# nrf7140_wificore register map
Vendor: Nordic Semiconductor; Series: nRF71; File version: 1
Registers are 32-bit, read-write, reset 0x0 unless marked. A register's access mark holds for its fields unless they carry their own. Offsets are from the block's base; [hi:lo] are bit positions; lines under a group give offsets from that group; {n}, {i} and the like mark numbered series.

## GLOBAL_COEXC — Coexistence controller
Base 0x5F92E000
{0x400+0x20*i} CCMALLOW[{i}] (i=0..5) group — Unspecified
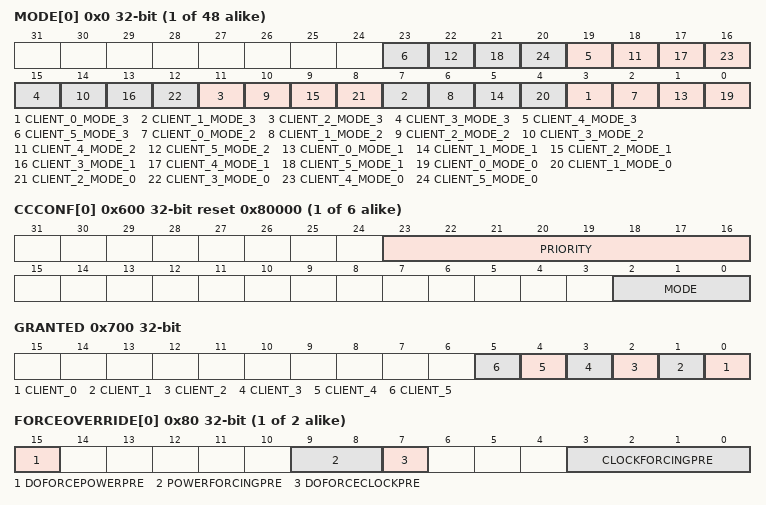
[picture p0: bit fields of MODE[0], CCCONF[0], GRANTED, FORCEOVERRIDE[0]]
  {0x0+4j} MODE[{j}] (j=0..7) — Description collection: Coexistence client mode allow configuration for mode [o] in client [n]
    [all] fields
      0=NotAllowed (Coexistence not allowed); 1=Allow (Coexistence allowed)
    [4n+3] CLIENT_{n}_MODE_3 (n=0..5) — Coexistence allowed configuration for mode [3] in client [{n}]
    [4n+2] CLIENT_{n}_MODE_2 (n=0..5) — Coexistence allowed configuration for mode [2] in client [{n}]
    [4n+1] CLIENT_{n}_MODE_1 (n=0..5) — Coexistence allowed configuration for mode [1] in client [{n}]
    [4n] CLIENT_{n}_MODE_0 (n=0..5) — Coexistence allowed configuration for mode [0] in client [{n}]
{0x600+4i} CCCONF[{i}] (i=0..5) reset 0x80000 — Description collection: Configuration of coexistence client [n]
  [23:16] PRIORITY — Priority of the coexistence client [n]
  [2:0] MODE — Coexistence mode of the client [m]
{0x640+4i} TURNAROUND[{i}] (i=0..5) reset 0x280 — Description collection: Turnaround time for the coexistence client [n]
  [11:0] CLOCKCYCLES — Number of clock cycles
0x700 GRANTED ro — Granted status of the shared resource
  [n] CLIENT_{n} (n=0..5) — Granted status coexistence client [{n}]
    0=NotGranted (Shared resource is not granted for coexistence client [{n}]); 1=Granted (Shared resource is granted for coexistence client [{n}])
0xC00 PCGCSLAVE group — Unspecified
  {0x0+4j} PENALTY[{j}] (j=0..1) reset 0xFFFFFFFC — Description collection: Penalty level for power/clock pair n. When FULL_PCP_ZERO feature is not supported, PENALTY[0] address overlaps the PENALTY0 address and register description for PENALTY[0] is not valid.
    [1:0] PENALTY — Penalty level
  0x00 PENALTY0 (alternate view of PENALTY[*]) — Penalty level for power/clock pair 0. The register description is valid only when FULL_PCP_ZERO feature is not supported
    [1:0] PENALTY ro — Penalty level
  {0x80+4j} FORCEOVERRIDE[{j}] (j=0..1) — Description collection: Force override of power/clock pair n.
    [15] DOFORCEPOWERPRE, [9:8] POWERFORCINGPRE, [7] DOFORCECLOCKPRE, [3:0] CLOCKFORCINGPRE

## GLOBAL_GPIOINTERNAL — GPIO Internal
Base 0x5F939E00
0x40 LATCHCLRWAITCNT reset 0x2 — Select the number of wait cycles inserted on the bus when a LATCH register is cleared.
  [1:0] LATCHCLRWAITCNT
0x44 FORCELDETECTLOWCNT reset 0x8 — Select the number of cycles that LDETECT is forced low after clearing a LATCH register.
  [3:0] FORCELDETECTLOWCNT
0x48 RESET — Reset all GPIO registers.
  [0] RESET
    1=RESET (Trigger reset); 0=NA (No effect)
0x4C SENSECONFIGCHANGECNT reset 0x3 — Selects the number of cycles before the SENSE configuration takes effect when it is changed. Setting this register lower than the reset value can lead to unwanted LATCH set when SENSE and INPUT fields (PIN[n].CNF) are changed simultaneously.
  [2:0] SENSECONFIGCHANGECNT — Selects the number of cycles before the SENSE configuration takes effect when it is changed.
0x160 PCGC group — Unspecified
  0x00 TURNOFFAUTOCLOCKSOURCEREQ ro — No functionality
  {0x20+4j} PENALTY[{j}] (j=0..4) ro — Description collection: Penalty level for power/clock pair n
    [7:0] PENALTY — Penalty level
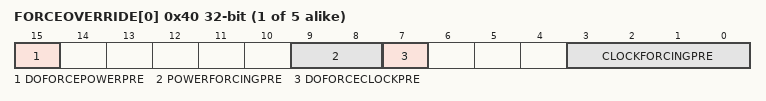
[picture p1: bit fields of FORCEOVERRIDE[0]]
  {0x40+4j} FORCEOVERRIDE[{j}] (j=0..4) ro — Description collection: Force override of power/clock pair n
    [15] DOFORCEPOWERPRE, [9:8] POWERFORCINGPRE, [7] DOFORCECLOCKPRE, [3:0] CLOCKFORCINGPRE

## GLOBAL_RESETHUB — Reset hub
Base 0x5F949000
{0x0+4i} TASKS_RESETDOMAIN[{i}] (i=0..10) wo — Description collection: Reset the domain [n], where n is domain id.
  [0] TASKS_RESETDOMAIN — Reset the domain [n], where n is domain id.
    1=Trigger task
{0x100+4i} EVENTS_DOMAINRESET[{i}] (i=0..10) — Description collection: Domain [n] was reset, where n is domain id.
  [0] EVENTS_DOMAINRESET — Domain [n] was reset, where n is domain id.
    0=NotGenerated (Event not generated); 1=Generated (Event generated)
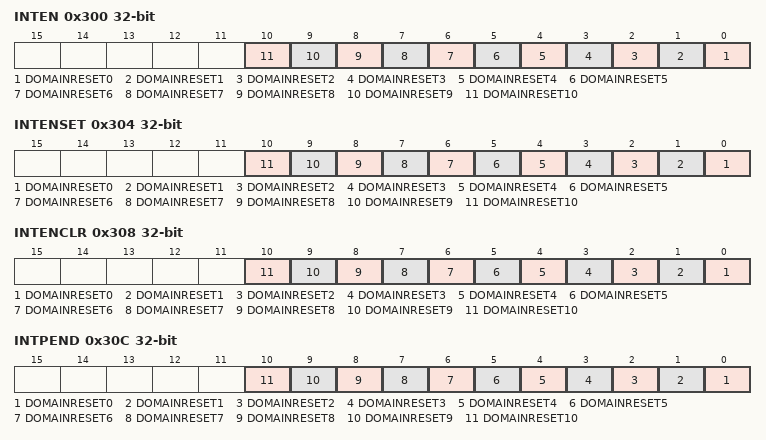
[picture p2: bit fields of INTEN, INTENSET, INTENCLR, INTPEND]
0x300 INTEN — Enable or disable interrupt
  [all] fields
    0=Disabled; 1=Enabled
  [n] DOMAINRESET{n} (n=0..10) — Enable or disable interrupt for event DOMAINRESET[{n}]
0x304 INTENSET — Enable interrupt
  [all] fields
    on read: 0=Disabled (Read: Disabled); 1=Enabled (Read: Enabled) | on write: 1=Set (Enable)
  [n] DOMAINRESET{n} (n=0..10) — Write '1' to enable interrupt for event DOMAINRESET[{n}]
0x308 INTENCLR — Disable interrupt
  [all] fields
    on read: 0=Disabled (Read: Disabled); 1=Enabled (Read: Enabled) | on write: 1=Clear (Disable)
  [n] DOMAINRESET{n} (n=0..10) — Write '1' to disable interrupt for event DOMAINRESET[{n}]
0x30C INTPEND ro — Pending interrupts
  [all] fields
    on read: 0=NotPending (Read: Not pending); 1=Pending (Read: Pending)
  [n] DOMAINRESET{n} (n=0..10) — Read pending status of interrupt for event DOMAINRESET[{n}]
0x400 RESETREAS group — Unspecified
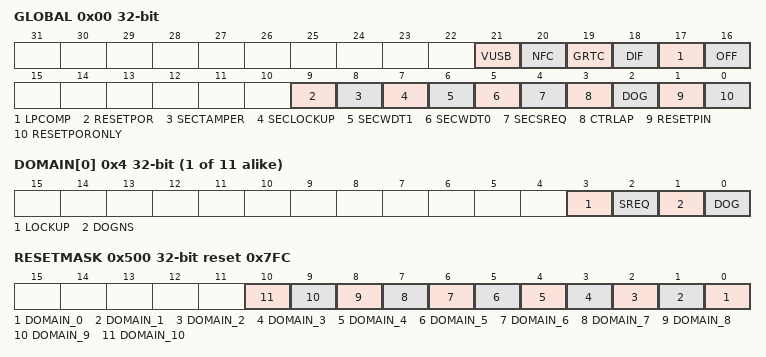
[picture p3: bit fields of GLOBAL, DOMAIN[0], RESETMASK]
  0x00 GLOBAL write-1-clears — Global reset reason.
    [all] fields
      0=NotDetected; 1=Detected
    [21] VUSB — Reset after wakeup from System OFF mode due to VBUS rising into valid range.
    [20] NFC — Reset due to wakeup from System OFF mode when wakeup is triggered by NFC field detection in sense mode.
    [19] GRTC — Reset due to wakeup from System OFF mode when wakeup is triggered by GRTC interrupt.
    [18] DIF — Reset due to wakeup from System OFF mode when wakeup is triggered by entering the debug interface mode.
    [17] LPCOMP — Reset due to wakeup from System OFF mode when wakeup is triggered by LPCOMP (Low Power Comparator).
    [16] OFF — Reset due to wakeup from System OFF mode when wakeup is triggered by DETECT signal from GPIO.
    [9] RESETPOR — Reset from power on reset (reset reason other than POR or BOR).
    [8] SECTAMPER — Reset due to secure domain tamper detected
    [7] SECLOCKUP — Reset due to secure domain lockup.
    [6] SECWDT1 — Reset due to the second instance of watchdog timer in secure domain detected.
    [5] SECWDT0 — Reset due to the first instance of watchdog timer in secure domain detected.
    [4] SECSREQ — Reset due to secure domain system reset request.
    [3] CTRLAP — Reset from CTRL-AP detected.
    [2] DOG — Reset from the SysCtrl watchdog timer detected.
    [1] RESETPIN — Reset from pin reset detected.
    [0] RESETPORONLY — Reset from power on reset (reset reason POR or BOR).
  {0x4+4j} DOMAIN[{j}] (j=0..10) write-1-clears — Description collection: Reset reason for the domain[n], where n is domain id.
    [all] fields
      0=NotDetected; 1=Detected
    [3] LOCKUP — Reset from local CPU lockup detected
    [2] SREQ — Reset from the local soft reset request detected.
    [1] DOGNS — Reset from the local non-secure watchdog timer detected
    [0] DOG — Reset from the local watchdog timer detected
0x500 RESETMASK reset 0x7FC — Mask the reset request for a domain by itself.
  [all] fields
    0=Mask the reset request; 1=Unmask the reset request
  [n] DOMAIN_{n} (n=0..10) — Mask the reset request for the domain[{n}], where [{n}] is domain id.
0x508 GPREGRET — General purpose retention register.
  [7:0] GPREGRET
